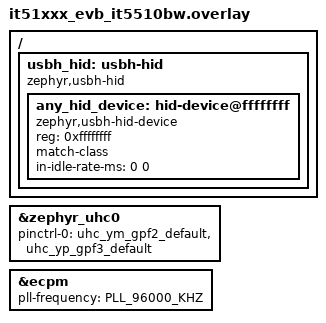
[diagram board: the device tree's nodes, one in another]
/*
 * Copyright (c) 2026 ITE Corporation. All Rights Reserved.
 *
 * SPDX-License-Identifier: Apache-2.0
 */

/ {
	usbh_hid: usbh-hid {
		compatible = "zephyr,usbh-hid";

		#address-cells = <1>;
		#size-cells = <0>;

		any_hid_device: hid-device@ffffffff {
			compatible = "zephyr,usbh-hid-device";
			reg = <0xffffffff>;
			match-class;
			in-idle-rate-ms = <0 0>;
			status = "okay";
		};
	};
};

&zephyr_uhc0 {
	status = "okay";

	pinctrl-0 = <&uhc_ym_gpf2_default &uhc_yp_gpf3_default>;
	pinctrl-names = "default";
};

&ecpm {
	pll-frequency = <PLL_96000_KHZ>;
};
